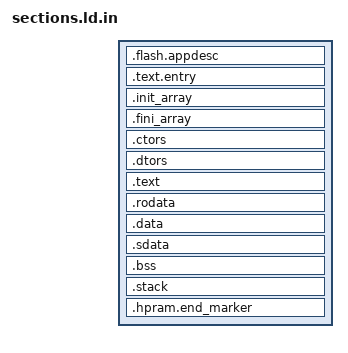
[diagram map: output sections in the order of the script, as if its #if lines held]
#include "sdkconfig.h"
#include "ld.common"
#include "esp_amp_mem_priv.h"

ENTRY(_start)

SECTIONS
{
  .flash.appdesc :
  {
    *(.rodata_desc .rodata_desc.*)
  } > app_desc

  . = ORIGIN(ram);

  .text.entry :
  {
    . = ALIGN(0x40);
    ASSERT(ABSOLUTE(.) % 0x40 == 0, "vector address must be 64 byte aligned");
    KEEP(*(.exception_vectors_table.text));
    KEEP(*(.exception_vectors.text));
    KEEP(*(.text.entry))
  } > ram

  .init_array :
  {
    PROVIDE_HIDDEN (__init_array_start = .);
    KEEP (*(SORT_BY_INIT_PRIORITY(.init_array.*) SORT_BY_INIT_PRIORITY(.ctors.*)))
    KEEP (*(.init_array EXCLUDE_FILE (*crtbegin.o *crtbegin?.o *crtend.o *crtend?.o ) .ctors))
    PROVIDE_HIDDEN (__init_array_end = .);
  } > ram

  .fini_array :
  {
    PROVIDE_HIDDEN (__fini_array_start = .);
    KEEP (*(SORT_BY_INIT_PRIORITY(.fini_array.*) SORT_BY_INIT_PRIORITY(.dtors.*)))
    KEEP (*(.fini_array EXCLUDE_FILE (*crtbegin.o *crtbegin?.o *crtend.o *crtend?.o ) .dtors))
    PROVIDE_HIDDEN (__fini_array_end = .);
  } > ram

  .ctors :
  {
    KEEP (*crtbegin.o(.ctors))
    KEEP (*crtbegin?.o(.ctors))
    KEEP (*(EXCLUDE_FILE (*crtend.o *crtend?.o ) .ctors))
    KEEP (*(SORT(.ctors.*)))
    KEEP (*(.ctors))
  } > ram

  .dtors :
  {
    KEEP (*crtbegin.o(.dtors))
    KEEP (*crtbegin?.o(.dtors))
    KEEP (*(EXCLUDE_FILE (*crtend.o *crtend?.o ) .dtors))
    KEEP (*(SORT(.dtors.*)))
    KEEP (*(.dtors))
  } > ram

  .text ALIGN(4):
  {
    mapping[text]
  } > ram

  .rodata ALIGN(4):
  {
    mapping[rodata]
  } > ram

  .data ALIGN(4):
  {
    __DATA_BEGIN__ = .;
    mapping[data]
  } > ram

  .sdata ALIGN(4):
  {
    __SDATA_BEGIN__ = .;
    *(.sdata .sdata.* .gnu.linkonce.s.*)
  }
  . = ALIGN(4);
  _edata = .; 
  PROVIDE (edata = .);

  .bss ALIGN(4):
  {
    mapping[bss]
  } > ram

  . = ALIGN(8);
  _end = .;
  __BSS_END__ = .;
  __global_pointer$ = MIN(
    __SDATA_BEGIN__ + 0x800,
    MAX(__DATA_BEGIN__ + 0x800, __BSS_END__ - 0x800)
  );
  PROVIDE (end = .);

#if CONFIG_ESP_AMP_SUBCORE_ENABLE_HEAP
  __heap_start = .;
  . += CONFIG_ESP_AMP_SUBCORE_HEAP_SIZE;
  __heap_end = ALIGN(8);
#endif

  .stack :
  {
    __stack_bottom = .;
    __stack_size_min = CONFIG_ESP_AMP_SUBCORE_STACK_SIZE_MIN;
    __stack_top = __stack_bottom + __stack_size_min;
    ASSERT(__stack_bottom + __stack_size_min == __stack_top, "Error: no space for stack");
  }

  . = __stack_top;

  .hpram.end_marker ALIGN(4):
  {
      LONG(0x050a050a)
      LONG(0x050a050a)
  } > ram

#include "elf_misc.ld.in"
}
